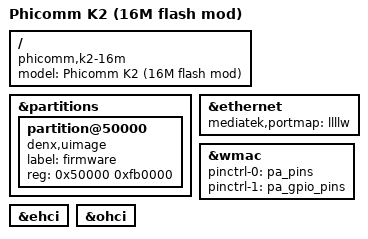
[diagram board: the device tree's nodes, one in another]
// SPDX-License-Identifier: GPL-2.0-or-later

#include "mt7620a_phicomm_k2x.dtsi"

/ {
	compatible = "phicomm,k2-16m", "ralink,mt7620a-soc";
	model = "Phicomm K2 (16M flash mod)";
};

&partitions {
	partition@50000 {
		compatible = "denx,uimage";
		label = "firmware";
		reg = <0x50000 0xfb0000>;
	};
};

&ethernet {
	mediatek,portmap = "llllw";
};

&wmac {
	pinctrl-names = "default", "pa_gpio";
	pinctrl-0 = <&pa_pins>;
	pinctrl-1 = <&pa_gpio_pins>;
};

/*
 * USB 2.0
 *
 * 与 32M 版一致：mt7620a.dtsi 里 ehci / ohci 默认 status = "disabled"，
 * 原厂 K2 无 USB 口。硬件改造（焊 USB 座 + D+/D- 接 MT7620A）后需打开。
 * 16M 与 32M 用的是同一块主板，USB 能力相同。
 */
&ehci {
	status = "okay";
};

&ohci {
	status = "okay";
};
